# ISD9300_v3 register map
File version: 1.0
Registers are 32-bit, read-write, reset 0x0 unless marked. A register's access mark holds for its fields unless they carry their own. Offsets are from the block's base; [hi:lo] are bit positions.

## I2S — I2S Register Map
Base 0x400A0000
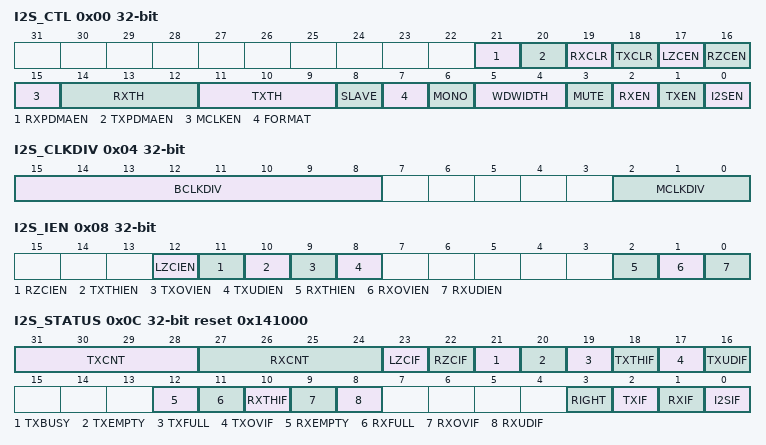
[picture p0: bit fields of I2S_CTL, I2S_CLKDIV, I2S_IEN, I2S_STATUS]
0x00 I2S_CTL — I2S Control Register
  [21] RXPDMAEN — Enable Receive DMA. When RX DMA is enabled, I2S requests DMA to transfer data from receive FIFO to SRAM if FIFO is not empty.
    0=Disable RX DMA; 1=Enable RX DMA
  [20] TXPDMAEN — Enable Transmit DMA. When TX DMA is enables, I2S request DMA to transfer data from SRAM to transmit FIFO if FIFO is not full.
    0=Disable TX DMA; 1=Enable TX DMA
  [19] RXCLR — Clear Receive FIFO. Write 1 to clear receive FIFO, internal pointer is reset to FIFO start point, and I2S_STATUS.RXCNT[3:0] returns to zero and receive FIFO becomes empty. This bit is cleared by hardware automatically when clear operation complete.
  [18] TXCLR — Clear Transmit FIFO. Write 1 to clear transmit FIFO, internal pointer is reset to FIFO start point, and I2S_STATUS.TXCNT[3:0] returns to zero and transmit FIFO becomes empty. Data in transmit FIFO is not changed. This bit is cleared by hardware automatically when clear operation complete.
  [17] LZCEN — Left Channel Zero Cross Detect Enable. If this bit is set to 1, when left channel data sign bit changes, or data bits are all zero, the LZCIF flag in I2S_STATUS register will be set to 1.
    0=Disable left channel zero cross detect; 1=Enable left channel zero cross detect
  [16] RZCEN — Right Channel Zero Cross Detect Enable. If this bit is set to 1, when right channel data sign bit changes, or data bits are all zero, the RZCIF flag in I2S_STATUS register will be set to 1.
    0=Disable right channel zero cross detect; 1=Enable right channel zero cross detect
  [15] MCLKEN — Master Clock Enable. The ISD9160 can generate a master clock signal to an external audio CODEC to synchronize the audio devices. If audio devices are not synchronous, then data will be periodically corrupted. Software needs to implement a way to drop/repeat or interpolate samples in a jitter buffer if devices are not synchronized. The master clock frequency is determined by the I2S_CLKDIV.MCLKDIV[2:0] register.
    0=Disable master clock; 1=Enable master clock
  [14:12] RXTH — Receive FIFO Threshold Level. When received data word(s) in buffer is equal or higher than threshold level then RXTHI flag is set.
  [11:9] TXTH — Transmit FIFO Threshold Level. If remaining data words in transmit FIFO less than or equal to the threshold level then TXTHI flag is set.
  [8] SLAVE — Slave Mode. I2S can operate as a master or slave. For master mode, I2S_BCLK and I2S_FS pins are outputs and send bit clock and frame sync from ISD9160. In slave mode, I2S_BCLK and I2S_FS pins are inputs and bit clock and frame sync are received from external audio device.
    0=Master mode; 1=Slave mode
  [7] FORMAT — Data Format. See Figure 561 and Figure 562 for timing differences.
    0=I2S data format; 1=MSB justified data format
  [6] MONO — Monaural Data. This parameter sets whether mono or stereo data is processed. See Figure 563 for details of how data is formatted in transmit and receive FIFO.
    0=Data is stereo format; 1=Data is monaural format
  [5:4] WDWIDTH — Word Width. This parameter sets the word width of audio data. See Figure 563 for details of how data is formatted in transmit and receive FIFO.
    0=data is 8 bit; 1=data is 16 bit; 2=data is 24 bit; 3=data is 32 bit
  [3] MUTE — Transmit Mute Enable
    0=Transmit data is shifted from FIFO; 1=Transmit channel zero
  [2] RXEN — Receive Enable
    0=Disable data receive; 1=Enable data receive
  [1] TXEN — Transmit Enable
    0=Disable data transmit; 1=Enable data transmit
  [0] I2SEN — Enable I2S Controller
    0=Disable; 1=Enable
0x04 I2S_CLKDIV — I2S Clock Divider Register
  [15:8] BCLKDIV — Bit Clock Divider. If I2S operates in master mode, bit clock is provided by ISD9160. Software can program these bits to generate bit clock frequency for the desired sample rate. For sample rate Fs, the desired bit clock frequency is: F(BCLK) aaa Fs x Word_width_in_bytes x 16. For example if Fs aaa 16kHz, and word width is 2-bytes (16bit) then desired bit clock frequency is 512kHz. The bit clock frequency is given by: F(BCLK) aaa F(I2S_CLKDIV) / 2x(BCLKDIV+1). Or, BCLKDIV aaa F(I2S_CLKDIV) / (2 x F(BCLK)) -1. So if F(I2S_CLKDIV) aaa HCLK aaa 49.152MHz , desired F(BCLK) aaa 512kHz then BCLKDIV aaa 47
  [2:0] MCLKDIV — Master Clock Divider. ISD9160 can generate a master clock to synchronously drive an external audio device. If MCLKDIV is set to 0, MCLK is the same as I2S_CLKDIV clock input, otherwise MCLK frequency is given by: F(MCLK) aaa F(I2S_CLKDIV) / (2xMCLKDIV). Or, MCLKDIV aaa F(I2S_CLKDIV) / (2 x F(MCLK)). If the desired MCLK frequency is 254Fs and Fs aaa 16kHz then MCLKDIV aaa 6
0x08 I2S_IEN — I2S Interrupt Enable Register
  [all] fields
    0=Disable interrupt; 1=Enable interrupt
  [12] LZCIEN — Left Channel Zero Cross Interrupt Enable. Interrupt will occur if this bit is set to 1 and left channel has zero cross event
  [11] RZCIEN — Right Channel Zero Cross Interrupt Enable. Interrupt will occur if this bit is set to 1 and right channel has zero cross event
  [10] TXTHIEN — Transmit FIFO Threshold Level Interrupt Enable. Interrupt occurs if this bit is set to 1 and data words in transmit FIFO is less than TXTH[2:0].
  [9] TXOVIEN — Transmit FIFO Overflow Interrupt Enable. Interrupt occurs if this bit is set to 1 and transmit FIFO overflow flag is set to 1
  [8] TXUDIEN — Transmit FIFO Underflow Interrupt Enable. Interrupt occur if this bit is set to 1 and transmit FIFO underflow flag is set to 1.
  [2] RXTHIEN — Receive FIFO Threshold Level Interrupt. Interrupt occurs if this bit is set to 1 and data words in receive FIFO is greater than or equal to RXTH[2:0].
  [1] RXOVIEN — Receive FIFO Overflow Interrupt Enable
  [0] RXUDIEN — Receive FIFO Underflow Interrupt Enable. If software read receive FIFO when it is empty then RXUDIF flag in I2SSTATUS register is set to 1.
0x0C I2S_STATUS reset 0x141000
  [31:28] TXCNT ro — Transmit FIFO Level (Read Only)
  [27:24] RXCNT ro — Receive FIFO Level (Read Only)
  [23] LZCIF — Left Channel Zero Cross Flag (Write '1' To Clear, Or Clear LZCEN)
    0=No zero cross detected; 1=Left channel zero cross is detected
  [22] RZCIF — Right Channel Zero Cross Flag (Write '1' To Clear, Or Clear RZCEN)
    0=No zero cross; 1=Right channel zero cross is detected
  [21] TXBUSY ro — Transmit Busy (Read Only). This bit is cleared when all data in transmit FIFO and Tx shift register is shifted out. It is set when first data is loaded to Tx shift register.
    0=Transmit shift register is empty; 1=Transmit shift register is busy
  [20] TXEMPTY ro — Transmit FIFO Empty (Read Only). This is set when transmit FIFO is empty.
    0=Not empty; 1=Empty
  [19] TXFULL ro — Transmit FIFO Full (Read Only). This bit is set when transmit FIFO is full.
    0=Not full; 1=Full
  [18] TXTHIF ro — Transmit FIFO Threshold Flag (Read Only). When data word(s) in transmit FIFO is less than or equal to the threshold value set in TXTH[2:0] the TXTHIF bit becomes to 1. It remains set until transmit FIFO level is greater than TXTH[2:0]. Cleared by writing to I2S_TX register until threshold exceeded.
    0=Data word(s) in FIFO is greater than threshold level; 1=Data word(s) in FIFO is less than or equal to threshold level
  [17] TXOVIF — Transmit FIFO Overflow Flag (Write '1' To Clear). This flag is set if data is written to transmit FIFO when it is full.
    0=No overflow; 1=Overflow
  [16] TXUDIF — Transmit FIFO Underflow Flag (Write '1' To Clear). This flag is set if I2S controller requests data when transmit FIFO is empty.
    0=No underflow; 1=Underflow
  [12] RXEMPTY ro — Receive FIFO Empty (Read Only). This is set when receive FIFO is empty.
    0=Not empty; 1=Empty
  [11] RXFULL ro — Receive FIFO Full (Read Only). This bit is set when receive FIFO is full.
    0=Not full; 1=Full
  [10] RXTHIF ro — Receive FIFO Threshold Flag (Read Only). When data word(s) in receive FIFO is greater than or equal to threshold value set in RXTH[2:0] the RXTHIF bit becomes to 1. It remains set until receive FIFO level is less than RXTH[2:0]. It is cleared by reading I2S_RX until threshold satisfied.
    0=Data word(s) in FIFO is less than threshold level; 1=Data word(s) in FIFO is greater than or equal to threshold level
  [9] RXOVIF — Receive FIFO Overflow Flag (Write '1' To Clear). This flag is set if I2S controller writes to receive FIFO when it is full. Audio data is lost.
    0=No overflow; 1=Overflow
  [8] RXUDIF — Receive FIFO Underflow Flag (Write '1' To Clear). This flag is set if attempt is made to read receive FIFO while it is empty.
    0=No underflow; 1=Underflow
  [3] RIGHT ro — Right Channel Active (Read Only). This bit indicates current data being transmitted/received belongs to right channel
    0=Left channel; 1=Right channel
  [2] TXIF ro — I2S Transmit Interrupt (Read Only). This indicates that there is an active transmit interrupt source. This could be TXOVIF, TXUDIF, TXTHIF, LZCIF or RZCIF if corresponding interrupt enable bits are active. To clear interrupt the corresponding source(s) must be cleared.
    0=No transmit interrupt; 1=Transmit interrupt occurred
  [1] RXIF ro — I2S Receive Interrupt (Read Only). This indicates that there is an active receive interrupt source. This could be RXOVIF, RXUDIF or RXTHIF if corresponding interrupt enable bits are active. To clear interrupt the corresponding source(s) must be cleared.
    0=No receive interrupt; 1=Receive interrupt occurred
  [0] I2SIF ro — I2S Interrupt (Read Only). This bit is set if any enabled I2S interrupt is active.
    0=No I2S interrupt; 1=I2S interrupt active
0x10 I2S_TX wo — I2S Transmit FIFO Register
  [31:0] TX — Transmit FIFO Register (Write Only). A write to this register pushes data onto the transmit FIFO. The transmit FIFO is eight words deep. The number of words currently in the FIFO can be determined by reading I2S_STATUS.TXCNT.
0x14 I2S_RX ro — I2S Receive FIFO Register
  [31:0] RX — Receive FIFO Register (Read Only). A read of this register will pop data from the receive FIFO. The receive FIFO is eight words deep. The number of words currently in the FIFO can be determined by reading I2S_STATUS.RXCNT.
